# PIC18F54Q71 register map
Vendor: Microchip
Registers are 8-bit, read-write, reset 0x0 unless marked. A register's access mark holds for its fields unless they carry their own. Addresses are absolute, and some are shared; only a register's first bit layout is shown; [hi:lo] are bit positions; {n}, {i} and the like mark numbered series; 'fields as' and 'values as' point back to an identical list.

## uart_protocol
0x2A0 U1RXB ro
  [7:0] RXB
0x2A1 U1RXCHK
  [7:0] RXCHK
0x2A2 U1TXB
  [7:0] TXB
0x2A3 U1TXCHK
  [7:0] TXCHK
0x2A4 U1P1L
  [7:0] P1L
{0x2A3+2i} U1P{i}H (i=1..3)
  [0] P{i}H
0x2A6 U1P2L
  [7:0] P2L
0x2A8 U1P3L reset not defined — (power-on value xxxxxxxx)
  [7:0] P3L
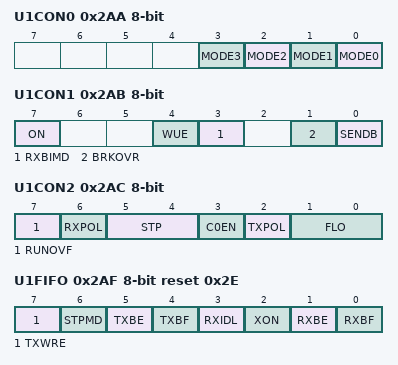
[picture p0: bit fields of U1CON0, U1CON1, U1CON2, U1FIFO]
0x2AA U1CON0
  [n] MODE{n} (n=0..3)
0x2AB U1CON1
  [7] ON, [4] WUE, [3] RXBIMD, [1] BRKOVR, [0] SENDB
0x2AC U1CON2
  [7] RUNOVF, [6] RXPOL, [5:4] STP, [3] C0EN, [2] TXPOL, [1:0] FLO
0x2AD U1BRGL
  [7:0] BRGL
0x2AE U1BRGH
  [7:0] BRGH
0x2AF U1FIFO reset 0x2E
  [7] TXWRE, [6] STPMD, [5] TXBE, [4] TXBF ro, [3] RXIDL ro, [2] XON ro, [1] RXBE ro, [0] RXBF ro
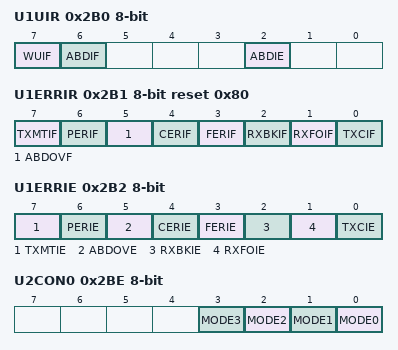
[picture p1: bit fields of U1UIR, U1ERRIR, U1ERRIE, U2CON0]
0x2B0 U1UIR
  [7] WUIF, [6] ABDIF, [2] ABDIE
0x2B1 U1ERRIR reset 0x80
  [7] TXMTIF, [6] PERIF, [5] ABDOVF, [4] CERIF, [3] FERIF, [2] RXBKIF, [1] RXFOIF, [0] TXCIF
0x2B2 U1ERRIE
  [7] TXMTIE, [6] PERIE, [5] ABDOVE, [4] CERIE, [3] FERIE, [2] RXBKIE, [1] RXFOIE, [0] TXCIE
0x2B4 U2RXB ro
  [7:0] RXB
0x2B6 U2TXB
  [7:0] TXB
0x2B8 U2P1L
  [7:0] P1L
0x2BA U2P2L
  [7:0] P2L
0x2BC U2P3L reset not defined — (power-on value xxxxxxxx)
  [7:0] P3L
0x2BE U2CON0
  [n] MODE{n} (n=0..3)
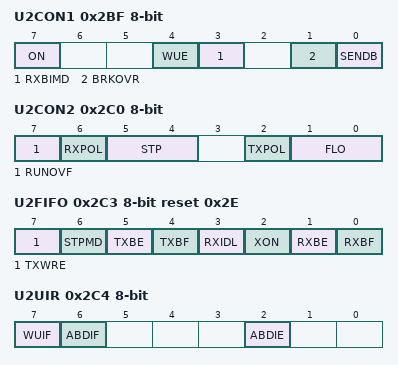
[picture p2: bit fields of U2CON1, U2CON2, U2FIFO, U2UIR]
0x2BF U2CON1
  [7] ON, [4] WUE, [3] RXBIMD, [1] BRKOVR, [0] SENDB
0x2C0 U2CON2
  [7] RUNOVF, [6] RXPOL, [5:4] STP, [2] TXPOL, [1:0] FLO
0x2C1 U2BRGL
  [7:0] BRGL
0x2C2 U2BRGH
  [7:0] BRGH
0x2C3 U2FIFO reset 0x2E
  fields as U1FIFO
0x2C4 U2UIR
  [7] WUIF, [6] ABDIF, [2] ABDIE
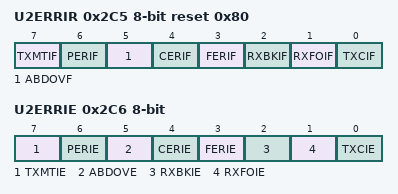
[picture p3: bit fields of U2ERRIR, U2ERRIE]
0x2C5 U2ERRIR reset 0x80
  fields as U1ERRIR
0x2C6 U2ERRIE
  fields as U1ERRIE

## tmr
0x312 TMR1L
0x313 TMR1H
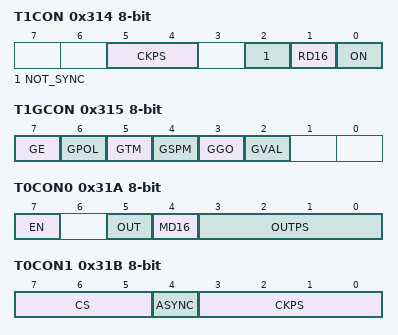
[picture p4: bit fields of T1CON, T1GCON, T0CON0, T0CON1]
0x314 T1CON
  [5:4] CKPS, [2] NOT_SYNC, [1] RD16, [0] ON
0x315 T1GCON reset not defined — (power-on value 00000x--)
  [7] GE, [6] GPOL, [5] GTM, [4] GSPM, [3] GGO, [2] GVAL ro
0x316 T1GATE
  [4:0] GSS
0x317 T1CLK
  [4:0] CS
0x318 TMR0L
0x319 TMR0H reset 0xFF
0x31A T0CON0
  [7] EN, [5] OUT ro, [4] MD16, [3:0] OUTPS
0x31B T0CON1
  [7:5] CS, [4] ASYNC, [3:0] CKPS
0x31D T2TMR — 8-bit period timer
  [7:0] TMR2
0x31E T2PR reset 0xFF
  [7:0] PR2
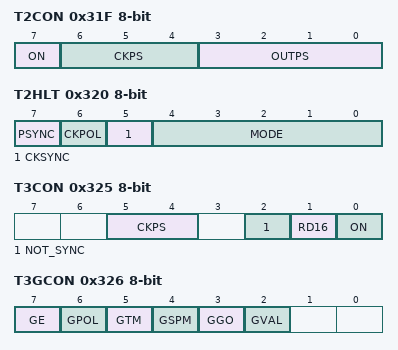
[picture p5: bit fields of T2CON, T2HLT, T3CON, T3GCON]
0x31F T2CON
  [7] ON, [6:4] CKPS, [3:0] OUTPS
0x320 T2HLT
  [7] PSYNC, [6] CKPOL, [5] CKSYNC, [4:0] MODE
0x321 T2CLKCON
  [4:0] CS
0x322 T2RST
  [4:0] RSEL
0x323 TMR3L
0x324 TMR3H
0x325 T3CON
  [5:4] CKPS, [2] NOT_SYNC, [1] RD16, [0] ON
0x326 T3GCON reset not defined — (power-on value 00000x--)
  [7] GE, [6] GPOL, [5] GTM, [4] GSPM, [3] GGO, [2] GVAL ro
0x327 T3GATE
  [4:0] GSS
0x328 T3CLK
  [4:0] CS
0x32A T4TMR — 8-bit period timer
  [7:0] TMR4
0x32B T4PR reset 0xFF
  [7:0] PR4
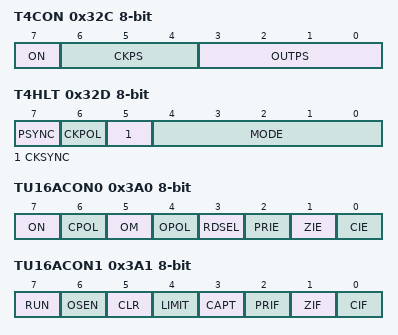
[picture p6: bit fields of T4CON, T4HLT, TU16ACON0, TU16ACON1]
0x32C T4CON
  [7] ON, [6:4] CKPS, [3:0] OUTPS
0x32D T4HLT
  [7] PSYNC, [6] CKPOL, [5] CKSYNC, [4:0] MODE
0x32E T4CLKCON
  [4:0] CS
0x32F T4RST
  [4:0] RSEL
0x3A0 TU16ACON0
  [7] ON, [6] CPOL, [5] OM, [4] OPOL, [3] RDSEL, [2] PRIE, [1] ZIE, [0] CIE
0x3A1 TU16ACON1
  [7] RUN ro, [6] OSEN, [5] CLR, [4] LIMIT, [3] CAPT, [2] PRIF, [1] ZIF, [0] CIF
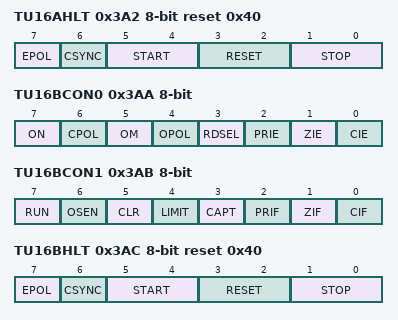
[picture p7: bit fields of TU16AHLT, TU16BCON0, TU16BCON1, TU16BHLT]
0x3A2 TU16AHLT reset 0x40
  [7] EPOL, [6] CSYNC, [5:4] START, [3:2] RESET, [1:0] STOP
0x3A3 TU16APS
  [7:0] PS
0x3A6 TU16APRL reset 0xFF
  [7:0] PRL
0x3A7 TU16APRH reset 0xFF
  [7:0] PRH
0x3A8 TU16ACLK
  [4:0] CLK
0x3A9 TU16AERS
  [4:0] ERS
0x3AA TU16BCON0
  fields as TU16ACON0
0x3AB TU16BCON1
  fields as TU16ACON1
0x3AC TU16BHLT reset 0x40
  [7] EPOL, [6] CSYNC, [5:4] START, [3:2] RESET, [1:0] STOP
0x3AD TU16BPS
  [7:0] PS
0x3B0 TU16BPRL reset 0xFF
  [7:0] PRL
0x3B1 TU16BPRH reset 0xFF
  [7:0] PRH
0x3B2 TU16BCLK
  [4:0] CLK
0x3B3 TU16BERS
  [4:0] ERS

## ccp
0x340 CCPR1L reset not defined — (power-on value xxxxxxxx)
  [7:0] RL
0x341 CCPR1H reset not defined — (power-on value xxxxxxxx)
  [7:0] RH
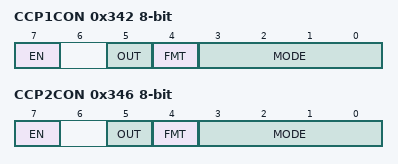
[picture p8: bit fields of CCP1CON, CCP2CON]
0x342 CCP1CON
  [7] EN, [5] OUT ro, [4] FMT, [3:0] MODE
0x343 CCP1CAP
  [3:0] CTS
0x344 CCPR2L reset not defined — (power-on value xxxxxxxx)
  [7:0] RL
0x345 CCPR2H reset not defined — (power-on value xxxxxxxx)
  [7:0] RH
0x346 CCP2CON
  [7] EN, [5] OUT ro, [4] FMT, [3:0] MODE
0x347 CCP2CAP
  [3:0] CTS
